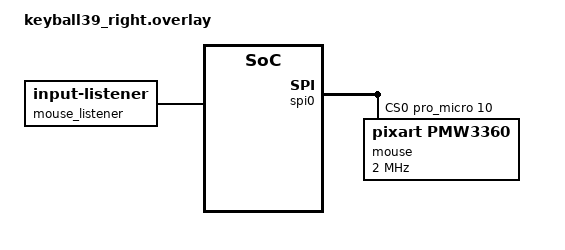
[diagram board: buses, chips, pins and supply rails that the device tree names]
// zmk/app/boards/shields/keyball39/keyball39_right.overlay
#include "keyball39.dtsi"

&default_transform { // The matrix transform for this board is 4 rows over because the left half is 4 rows tall according to the matrix.
    row-offset = <4>;
};

&spi0 {
    status = "okay";
    cs-gpios = <&pro_micro 10 (GPIO_ACTIVE_HIGH | GPIO_PULL_DOWN)>;

    mouse: mouse@0 {
        compatible = "pixart,pmw3360";
        status = "okay";
        reg = <0>;
        spi-max-frequency = <2000000>;
        cpi = <600>;
    };
};

/ {
    mouse_listener {
        compatible = "zmk,input-listener";
        device = <&mouse>;
    };
};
